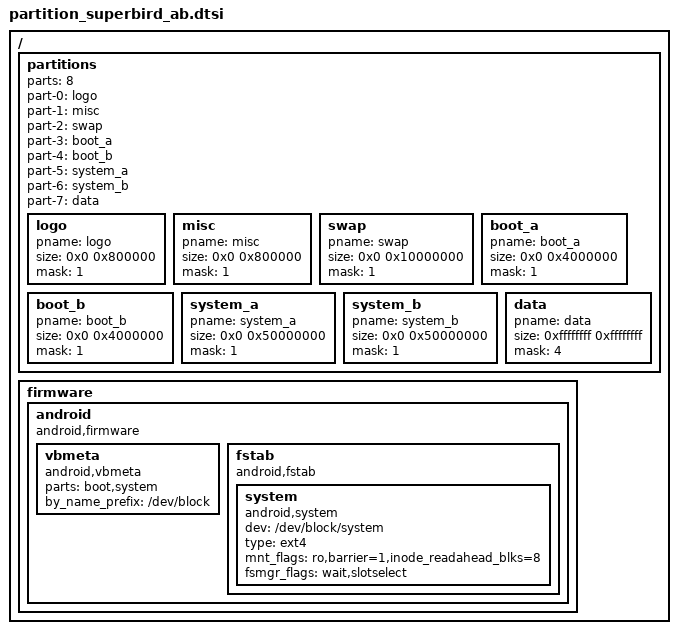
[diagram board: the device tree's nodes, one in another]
/*
 * Amlogic partition set for normal
 *
 * Copyright (c) 2017-2017 Amlogic Ltd
 *
 * This file is licensed under a dual GPLv2 or BSD license.
 * 
 * logo = boot logo 
 * tee = trusted execution environment (Android)
 * 
 */
/ {
	partitions: partitions{
		parts = <8>;
		part-0 = <&logo>;
		part-1 = <&misc>;
		part-2 = <&swap>;
		part-3 = <&boot_a>;
		part-4 = <&boot_b>;
		part-5 = <&system_a>;
		part-6 = <&system_b>;
		part-7 = <&data>;

		logo:logo{
			pname = "logo";
			size = <0x0 0x800000>; /* 8 MiB */
			mask = <1>;
		};
		misc:misc{
			pname = "misc";
			size = <0x0 0x800000>; /* 8 MiB */
			mask = <1>;
		};
		swap:swap{
			pname = "swap";
			size = <0x0 0x10000000>; /* 256 MiB */
			mask = <1>;
		};
		boot_a:boot_a{
			pname = "boot_a";
			size = <0x0 0x4000000>; /* 64 MiB */
			mask = <1>;
		};
		boot_b:boot_b{
			pname = "boot_b";
			size = <0x0 0x4000000>; /* 64 MiB */
			mask = <1>;
		};
		system_a:system_a{
			pname = "system_a";
			size = <0x0 0x50000000>; /* 1280 MiB */
			mask = <1>;
		};
		system_b:system_b{
			pname = "system_b";
			size = <0x0 0x50000000>; /* 1280 MiB */
			mask = <1>;
		};
		data:data{
			pname = "data";
			size = <0xffffffff 0xffffffff>;
			mask = <4>;
		};
	};

	firmware {
		android {
			compatible = "android,firmware";
			vbmeta {
				compatible = "android,vbmeta";
				parts = "boot,system";
				by_name_prefix="/dev/block";
			};
		fstab {
			compatible = "android,fstab";
			system {
				compatible = "android,system";
				dev = "/dev/block/system";
				type = "ext4";
				mnt_flags = "ro,barrier=1,inode_readahead_blks=8";
				fsmgr_flags = "wait,slotselect";
				};
			};
		};
	};

};/* end of / */
